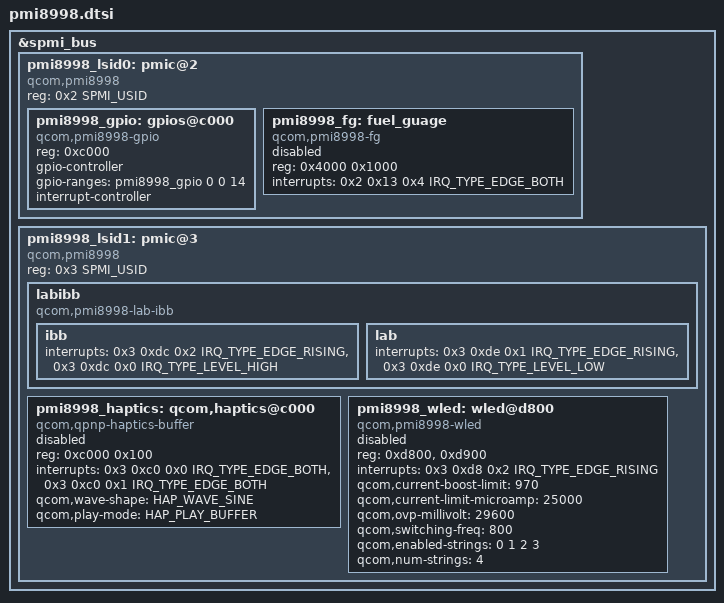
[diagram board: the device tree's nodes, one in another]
// SPDX-License-Identifier: GPL-2.0
#include <dt-bindings/input/qcom,pmi8998-haptics.h>
#include <dt-bindings/interrupt-controller/irq.h>
#include <dt-bindings/spmi/spmi.h>

&spmi_bus {
	pmi8998_lsid0: pmic@2 {
		compatible = "qcom,pmi8998", "qcom,spmi-pmic";
		reg = <0x2 SPMI_USID>;
		#address-cells = <1>;
		#size-cells = <0>;

		pmi8998_gpio: gpios@c000 {
			compatible = "qcom,pmi8998-gpio", "qcom,spmi-gpio";
			reg = <0xc000>;
			gpio-controller;
			gpio-ranges = <&pmi8998_gpio 0 0 14>;
			#gpio-cells = <2>;
			interrupt-controller;
			#interrupt-cells = <2>;
		};

		pmi8998_fg: fuel_guage {
			compatible = "qcom,pmi8998-fg";
			status = "disabled";
			#address-cells = <1>;
			#size-cells = <0>;
			       //FG  //Charger
			reg = <0x4000 0x1000>;
			interrupts = <0x2 0x13 0x4 IRQ_TYPE_EDGE_BOTH>;
			interrupt-names = "usb-plugin";
		};
	};

	pmi8998_lsid1: pmic@3 {
		compatible = "qcom,pmi8998", "qcom,spmi-pmic";
		reg = <0x3 SPMI_USID>;
		#address-cells = <1>;
		#size-cells = <0>;

		labibb {
			compatible = "qcom,pmi8998-lab-ibb";

			ibb: ibb {
				interrupts = <0x3 0xdc 0x2 IRQ_TYPE_EDGE_RISING>,
					     <0x3 0xdc 0x0 IRQ_TYPE_LEVEL_HIGH>;
				interrupt-names = "sc-err", "ocp";
			};

			lab: lab {
				interrupts = <0x3 0xde 0x1 IRQ_TYPE_EDGE_RISING>,
					     <0x3 0xde 0x0 IRQ_TYPE_LEVEL_LOW>;
				interrupt-names = "sc-err", "ocp";
			};
		};

		pmi8998_haptics: qcom,haptics@c000 {
			compatible = "qcom,qpnp-haptics-buffer";
			reg = <0xc000 0x100>;

			interrupts = <0x3 0xc0 0x0 IRQ_TYPE_EDGE_BOTH>,
						 <0x3 0xc0 0x1 IRQ_TYPE_EDGE_BOTH>;
			interrupt-names = "hap-sc-irq", "hap-play-irq"; 

			qcom,wave-shape = <HAP_WAVE_SINE>;
			qcom,play-mode = <HAP_PLAY_BUFFER>;

			status = "disabled";

			// Unused / unimplemented in code

			// qcom,lra-res-cal-period = <32>;
			// qcom,play-mode = "direct";
			// qcom,actuator-type = <HAP_TYPE_LRA>;
			// qcom,brake-pattern = <0x3 0x3 0x3 0x3>;
		};
		
		pmi8998_wled: wled@d800 {
			#address-cells = <1>;
			#size-cells = <0>;
			compatible = "qcom,pmi8998-wled";
			reg = <0xd800>, <0xd900>;
			interrupts = <0x3 0xd8 0x2 IRQ_TYPE_EDGE_RISING>;
			interrupt-names = "short";
			qcom,current-boost-limit = <970>;
			qcom,current-limit-microamp = <25000>;
			qcom,ovp-millivolt = <29600>;
			qcom,switching-freq = <800>;
			qcom,enabled-strings = <0 1 2 3>;
			qcom,num-strings = <4>;
			status = "disabled";
		};
	};
};
